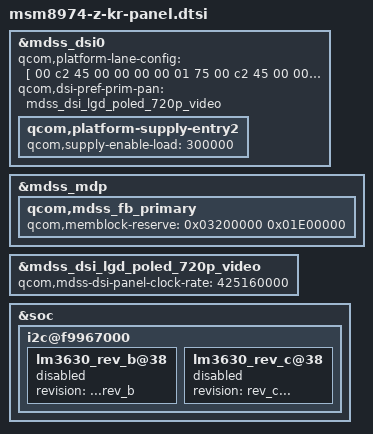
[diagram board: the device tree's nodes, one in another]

/* Copyright (c) 2012, Code Aurora Forum. All rights reserved.
 *
 * This program is free software; you can redistribute it and/or modify
 * it under the terms of the GNU General Public License version 2 and
 * only version 2 as published by the Free Software Foundation.
 *
 * This program is distributed in the hope that it will be useful,
 * but WITHOUT ANY WARRANTY; without even the implied warranty of
 * MERCHANTABILITY or FITNESS FOR A PARTICULAR PURPOSE.  See the
 * GNU General Public License for more details.
 */

&mdss_dsi0 {
	qcom,platform-lane-config = [
		00 c2 45 00 00 00 00 01 75 // lane0 config
		00 c2 45 00 00 00 00 01 75 // lane1 config
		00 c2 45 00 00 00 00 01 75 // lane2 config
		00 c2 45 00 00 00 00 01 75 // lane3 config
		00 02 45 00 00 00 00 01 97 // Clk ln config
	];
	qcom,dsi-pref-prim-pan = <&mdss_dsi_lgd_poled_720p_video>;
	qcom,platform-supply-entry2 {
		qcom,supply-enable-load = <300000>;
	};

};

&mdss_mdp {
	qcom,mdss_fb_primary {
		qcom,memblock-reserve = <0x03200000 0x01E00000>;
	};
};

&mdss_dsi_lgd_poled_720p_video {
	qcom,mdss-dsi-panel-clock-rate = <425160000>;
};

&soc {
	i2c@f9967000 {
		lm3630_rev_b@38 {
			status = "disable";
			revision = "...rev_b";
		};

		lm3630_rev_c@38 {
			status = "disable";
			revision = "rev_c...";
		};
	};
};
